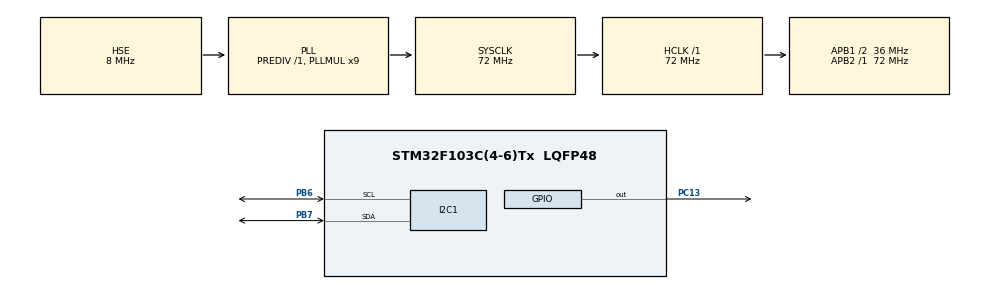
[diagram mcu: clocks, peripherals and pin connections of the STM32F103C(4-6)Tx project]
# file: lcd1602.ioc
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Mcu.Family=STM32F1
Mcu.Name=STM32F103C(4-6)Tx
Mcu.Package=LQFP48
NVIC.PriorityGroup=NVIC_PRIORITYGROUP_4
PB6.Mode=I2C
PB6.Signal=I2C1_SCL
PB7.Mode=I2C
PB7.Signal=I2C1_SDA
PC13-TAMPER-RTC.Signal=GPIO_Output
PD0-OSC_IN.Mode=HSE-External-Oscillator
PD0-OSC_IN.Signal=RCC_OSC_IN
PD1-OSC_OUT.Mode=HSE-External-Oscillator
PD1-OSC_OUT.Signal=RCC_OSC_OUT
ProjectManager.HeapSize=0x200
ProjectManager.StackSize=0x400
ProjectManager.TargetToolchain=STM32CubeIDE
RCC.AHBFreq_Value=72000000
RCC.APB1CLKDivider=RCC_HCLK_DIV2
RCC.APB1Freq_Value=36000000
RCC.APB1TimFreq_Value=72000000
RCC.APB2Freq_Value=72000000
RCC.APB2TimFreq_Value=72000000
RCC.HCLKFreq_Value=72000000
RCC.PLLMUL=RCC_PLL_MUL9
RCC.PLLSourceVirtual=RCC_PLLSOURCE_HSE
RCC.SYSCLKFreq_VALUE=72000000
RCC.SYSCLKSource=RCC_SYSCLKSOURCE_PLLCLK
RCC.USBFreq_Value=72000000
board=custom

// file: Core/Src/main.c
/* USER CODE BEGIN Header */
/**
  ******************************************************************************
  * @file           : main.c
  * @brief          : Main program body
  ******************************************************************************
  * @attention
  *
  * Copyright (c) 2023 STMicroelectronics.
  * All rights reserved.
  *
  * This software is licensed under terms that can be found in the LICENSE file
  * in the root directory of this software component.
  * If no LICENSE file comes with this software, it is provided AS-IS.
  *
  ******************************************************************************
  */
/* USER CODE END Header */
#include "main.h"

I2C_HandleTypeDef hi2c1;

/* USER CODE BEGIN PV */

uint16_t lcd_addr;

/* USER CODE END PV */

void SystemClock_Config(void);
static void MX_GPIO_Init(void);
static void MX_I2C1_Init(void);

int main(void)
{

  /* MCU Configuration--------------------------------------------------------*/

  /* Reset of all peripherals, Initializes the Flash interface and the Systick. */
  HAL_Init();

  /* Configure the system clock */
  SystemClock_Config();

  /* Initialize all configured peripherals */
  MX_GPIO_Init();
  MX_I2C1_Init();
  /* USER CODE BEGIN 2 */
  HAL_Delay(100);
  lcd_set_addr(I2C_LCD_WRITE1);
  lcd_init();
  lcd_send_string("LCD1");
  lcd_set_addr(I2C_LCD_WRITE2);
  lcd_init();
  lcd_send_string("LCD2");
  /* USER CODE END 2 */

  /* Infinite loop */
  while (1)
  {

    /* USER CODE BEGIN 3 */
	HAL_Delay(1000);
	HAL_GPIO_TogglePin(GPIOC, GPIO_PIN_13);
	lcd_set_cursor(1,0);
	lcd_send_string("1234567890");
	HAL_Delay(5000);
	lcd_clear();
	lcd_send_string("LCD2");
  }
  /* USER CODE END 3 */
}

void SystemClock_Config(void)
{
  RCC_OscInitTypeDef RCC_OscInitStruct = {0};
  RCC_ClkInitTypeDef RCC_ClkInitStruct = {0};

  /** Initializes the RCC Oscillators according to the specified parameters
  * in the RCC_OscInitTypeDef structure.
  */
  RCC_OscInitStruct.OscillatorType = RCC_OSCILLATORTYPE_HSE;
  RCC_OscInitStruct.HSEState = RCC_HSE_ON;
  RCC_OscInitStruct.HSEPredivValue = RCC_HSE_PREDIV_DIV1;
  RCC_OscInitStruct.HSIState = RCC_HSI_ON;
  RCC_OscInitStruct.PLL.PLLState = RCC_PLL_ON;
  RCC_OscInitStruct.PLL.PLLSource = RCC_PLLSOURCE_HSE;
  RCC_OscInitStruct.PLL.PLLMUL = RCC_PLL_MUL9;
  if (HAL_RCC_OscConfig(&RCC_OscInitStruct) != HAL_OK)
  {
    Error_Handler();
  }

  /** Initializes the CPU, AHB and APB buses clocks
  */
  RCC_ClkInitStruct.ClockType = RCC_CLOCKTYPE_HCLK|RCC_CLOCKTYPE_SYSCLK
                              |RCC_CLOCKTYPE_PCLK1|RCC_CLOCKTYPE_PCLK2;
  RCC_ClkInitStruct.SYSCLKSource = RCC_SYSCLKSOURCE_PLLCLK;
  RCC_ClkInitStruct.AHBCLKDivider = RCC_SYSCLK_DIV1;
  RCC_ClkInitStruct.APB1CLKDivider = RCC_HCLK_DIV2;
  RCC_ClkInitStruct.APB2CLKDivider = RCC_HCLK_DIV1;

  if (HAL_RCC_ClockConfig(&RCC_ClkInitStruct, FLASH_LATENCY_2) != HAL_OK)
  {
    Error_Handler();
  }
}

static void MX_I2C1_Init(void)
{

  hi2c1.Instance = I2C1;
  hi2c1.Init.ClockSpeed = 100000;
  hi2c1.Init.DutyCycle = I2C_DUTYCYCLE_2;
  hi2c1.Init.OwnAddress1 = 0;
  hi2c1.Init.AddressingMode = I2C_ADDRESSINGMODE_7BIT;
  hi2c1.Init.DualAddressMode = I2C_DUALADDRESS_DISABLE;
  hi2c1.Init.OwnAddress2 = 0;
  hi2c1.Init.GeneralCallMode = I2C_GENERALCALL_DISABLE;
  hi2c1.Init.NoStretchMode = I2C_NOSTRETCH_DISABLE;
  if (HAL_I2C_Init(&hi2c1) != HAL_OK)
  {
    Error_Handler();
  }

}

static void MX_GPIO_Init(void)
{
  GPIO_InitTypeDef GPIO_InitStruct = {0};

  /* GPIO Ports Clock Enable */
  __HAL_RCC_GPIOC_CLK_ENABLE();
  __HAL_RCC_GPIOD_CLK_ENABLE();
  __HAL_RCC_GPIOB_CLK_ENABLE();

  /*Configure GPIO pin Output Level */
  HAL_GPIO_WritePin(GPIOC, GPIO_PIN_13, GPIO_PIN_RESET);

  /*Configure GPIO pin : PC13 */
  GPIO_InitStruct.Pin = GPIO_PIN_13;
  GPIO_InitStruct.Mode = GPIO_MODE_OUTPUT_PP;
  GPIO_InitStruct.Pull = GPIO_NOPULL;
  GPIO_InitStruct.Speed = GPIO_SPEED_FREQ_LOW;
  HAL_GPIO_Init(GPIOC, &GPIO_InitStruct);

}

/* USER CODE BEGIN 4 */

void lcd_send_inst(char cmd)
{
	uint8_t data_t[4];
	char data_u = cmd & 0b11110000;
	data_t[0] = data_u | 0b00001100;  //BL=1, EN=1
	data_t[1] = data_u | 0b00001000;  //BL=1, EN=0
	char data_l = (cmd & 0b00001111) << 4;
	data_t[2] = data_l | 0b00001100;  //BL=1, EN=1
	data_t[3] = data_l | 0b00001000;  //BL=1, EN=0
	HAL_I2C_Master_Transmit(&hi2c1, lcd_addr, data_t, 4, 100);
	lcd_check_busy();
}

void lcd_send_data (char data)
{
	uint8_t data_t[4];
	char data_u = data & 0b11110000;
	data_t[0] = data_u | 0b00001101;  //BL=1, EN=1, RS=1
	data_t[1] = data_u | 0b00001001;  //BL=1, EN=0, RS=1
	char data_l = (data & 0b00001111) << 4;
	data_t[2] = data_l | 0b00001101;  //BL=1, EN=1, RS=1
	data_t[3] = data_l | 0b00001001;  //BL=1, EN=0, RS=1
	HAL_I2C_Master_Transmit(&hi2c1, lcd_addr, data_t, 4, 100);
	lcd_check_busy();
}

uint8_t lcd_check_busy(void)
{
	//TODO: read busy flag from lcd
	HAL_Delay(1);
	return 0;
}

void lcd_init(void)
{
	HAL_Delay(5);
	lcd_send_inst(0b00100000); // Init - 00 1 DL 0000; DL 8bit mode = 1, 4 bit mode = 0
	lcd_send_inst(0b00101000); // Init - 00 1 DL N F 00; N 2lines = 1; F fond pixel count
	lcd_clear();
	lcd_send_inst(0b00000110); // Set Cursor - 00000 1 I/D S; I/D - Inc/Dec 1/0; S - Shift/No Shift 1/0
	lcd_send_inst(0b00001100); // Set display - 0000 1 D C B; D - Display on/off 1/0; C - Cursor on/off 1/0; B - Blinking on/off 1/0
}

void lcd_send_string(char *str)
{
	while (*str) lcd_send_data (*str++);
}

void lcd_clear(void)
{
	lcd_send_inst(0b00000001); // Clear display - no params
	HAL_Delay(2);
}

void lcd_set_cursor(char row, char col)
{
	lcd_send_inst(col | (row > 0 ? 0xC0 : 0x80));
}

void lcd_set_addr(uint16_t addr)
{
	lcd_addr = addr;
}

/* USER CODE END 4 */

void Error_Handler(void)
{
  __disable_irq();
  while (1)
  {
  }
}
